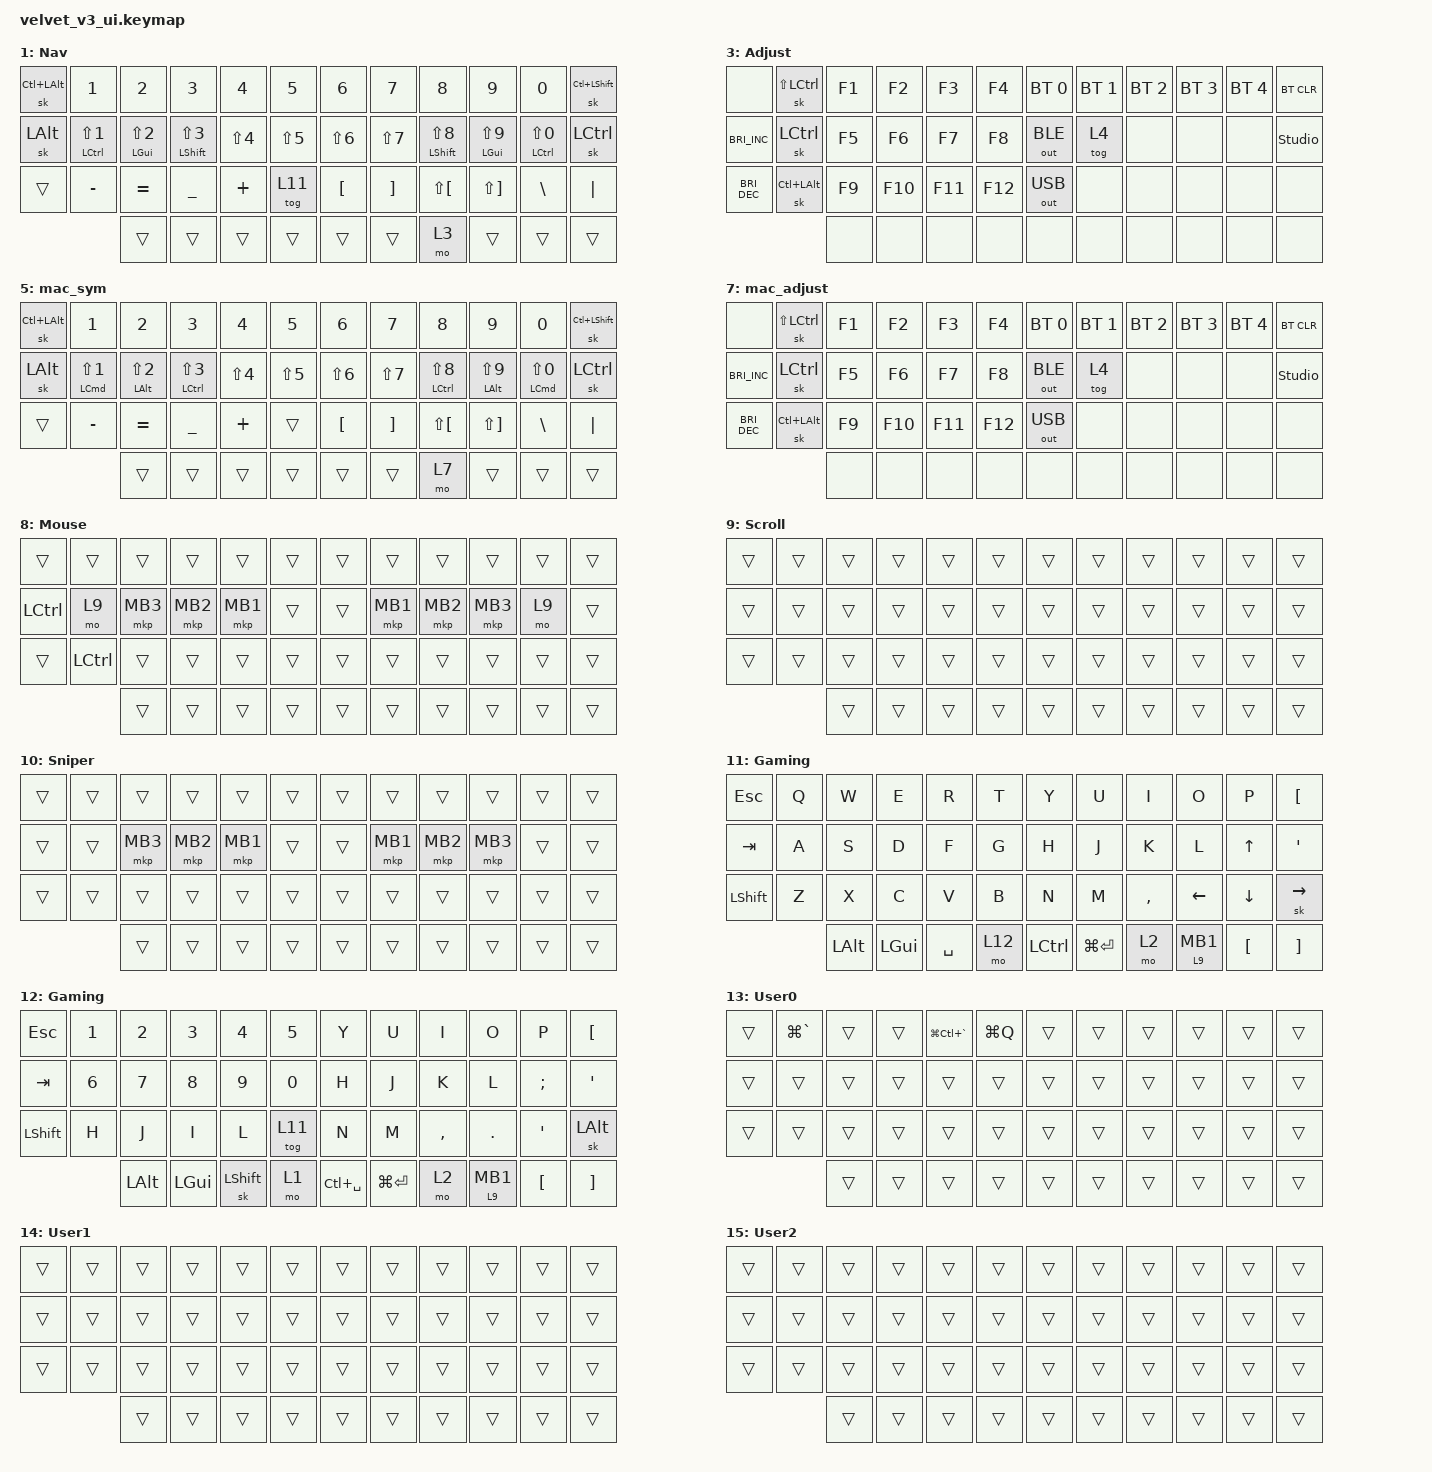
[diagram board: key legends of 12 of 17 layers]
#include "keys_ru.h"
#include <dt-bindings/zmk/input_transform.h>
#include <input/processors.dtsi>
#include <zephyr/dt-bindings/input/input-event-codes.h>
#include <behaviors.dtsi>
#include <dt-bindings/zmk/bt.h>
#include <dt-bindings/zmk/keys.h>
#include <dt-bindings/zmk/outputs.h>
#include <dt-bindings/zmk/pointing.h>

/ {
    behaviors {
        cap_sen: cap_sen {
            compatible = "zmk,behavior-hold-tap";
            label = "CAP_SEN";
            bindings = <&mo>, <&none>;

            #binding-cells = <2>;
            tapping-term-ms = <150>;
            hold-while-undecided;
        };

        hrm: hrm {
            compatible = "zmk,behavior-hold-tap";
            label = "HRM";
            bindings = <&kp>, <&kp>;

            #binding-cells = <2>;
            flavor = "balanced";
            tapping-term-ms = <200>;
            quick-tap-ms = <150>;
            require-prior-idle-ms = <50>;
        };

        th_cl: th_cl {
            compatible = "zmk,behavior-hold-tap";
            label = "TH_CL";
            bindings = <&mo>, <&kp>;

            #binding-cells = <2>;
            tapping-term-ms = <200>;
            flavor = "hold-preferred";
        };

        tball_mode: tball_mode {
            compatible = "zmk,behavior-hold-tap";
            label = "TBALL_MODE";
            bindings = <&mo>, <&tog>;

            #binding-cells = <2>;
            tapping-term-ms = <180>;
            flavor = "tap-preferred";
        };
    };

    combos {
        compatible = "zmk,combos";

        jk {
            bindings = <&jk LG(F12)>;
            key-positions = <19 20>;
            layers = <0 2 1 3>;
            require-prior-idle-ms = <50>;
        };

        ctrl-z {
            bindings = <&kp LC(Z)>;
            key-positions = <25 26>;
            require-prior-idle-ms = <50>;
            layers = <0 9 9>;
        };

        ctrl-x {
            bindings = <&kp LC(X)>;
            key-positions = <26 27>;
            require-prior-idle-ms = <50>;
            layers = <0 9 9>;
        };

        ctrl-c {
            bindings = <&kp LC(C)>;
            key-positions = <27 28>;
            require-prior-idle-ms = <50>;
            layers = <0 9 9>;
        };

        ctrl-v {
            bindings = <&kp LC(V)>;
            key-positions = <28 29>;
            require-prior-idle-ms = <50>;
            layers = <0 9 9>;
        };

        Escape {
            bindings = <&kp ESC>;
            key-positions = <2 3>;
            require-prior-idle-ms = <50>;
            layers = <0 9 9 9 4>;
        };

        m1 {
            bindings = <&mkp MB1>;
            key-positions = <15 16>;
            layers = <0 9 4>;
        };

        mk2 {
            bindings = <&mkp MB2>;
            key-positions = <16 17>;
            layers = <0 9 4>;
        };

        mk3 {
            bindings = <&mkp MB3>;
            key-positions = <16 17 15>;
            layers = <0 9 4>;
        };

        scroll {
            bindings = <&mo 9>;
            key-positions = <14 15>;
            layers = <0 9 4>;
        };

        mk3_double {
            bindings = <&mkp MB3>;
            key-positions = <44 45>;
        };

        jk_mac {
            bindings = <&kp LC(LEFT_BRACKET)>;
            key-positions = <19 20>;
            require-prior-idle-ms = <50>;
            layers = <9 4>;
        };

        macz {
            bindings = <&kp LG(Z)>;
            key-positions = <25 26>;
            require-prior-idle-ms = <50>;
            layers = <9 4>;
        };

        macx {
            bindings = <&kp LG(X)>;
            key-positions = <26 27>;
            require-prior-idle-ms = <50>;
            layers = <9 4>;
        };

        macc {
            bindings = <&kp LG(C)>;
            key-positions = <27 28>;
            require-prior-idle-ms = <50>;
            layers = <9 4>;
        };

        macv {
            bindings = <&kp LG(V)>;
            key-positions = <28 29>;
            require-prior-idle-ms = <50>;
            layers = <9 4>;
        };

        Sniper {
            bindings = <&mo 10>;
            key-positions = <3 4>;
        };
    };

    macros {
        jk: jk {
            compatible = "zmk,behavior-macro-one-param";
            #binding-cells = <1>;
            bindings =
                <&macro_param_1to1 &kp MACRO_PLACEHOLDER>,
                <&macro_wait_time 30>,
                <&kp LC(LEFT_BRACKET)>;

            label = "JK";
        };

        sen_mo: sen_mo {
            compatible = "zmk,behavior-macro-one-param";
            #binding-cells = <1>;
            bindings =
                <&macro_wait_time 80>,
                <&macro_press>,
                <&macro_param_1to1 &mo MACRO_PLACEHOLDER>,
                <&macro_pause_for_release>,
                <&macro_release>,
                <&macro_param_1to1 &mo MACRO_PLACEHOLDER>;

            label = "SEN_MO";
        };

        bt0_lin: bt0_lin {
            compatible = "zmk,behavior-macro";
            #binding-cells = <0>;
            bindings =
                <&macro_tap>,
                <&bt BT_SEL 0>,
                <&macro_tap>,
                <&tog 0>,
                <&macro_press>;

            label = "BT0_LIN";
        };

        bt1_mac: bt1_mac {
            compatible = "zmk,behavior-macro";
            #binding-cells = <0>;
            bindings =
                <&macro_tap>,
                <&tog 0>,
                <&macro_tap>,
                <&bt BT_SEL 1>,
                <&macro_tap>,
                <&tog 9>;

            label = "BT1_MAC";
        };
    };

    keymap {
        compatible = "zmk,keymap";

        base {
            bindings = <
&lt 13 GRAVE  &kp Q         &kp W            &kp E         &kp R           &kp T                                                                         &kp Y                        &kp U  &kp I      &kp O            &kp P            &kp LEFT_BRACKET
&kp TAB       &hrm LCTRL A  &hrm LEFT_GUI S  &kp D         &kp F           &hrm LS(LA(LC(LEFT_GUI))) G                                                   &hrm LS(LA(LC(LEFT_GUI))) H  &kp J  &kp K      &hrm LEFT_GUI L  &hrm LCTRL SEMI  &kp SINGLE_QUOTE
&caps_word    &kp Z         &kp X            &kp C         &kp V           &kp B                                                                         &kp N                        &kp M  &kp COMMA  &kp DOT          &kp SLASH        &sk LEFT_ALT
                            &kp LEFT_ALT     &kp CAPSLOCK  &sk LEFT_SHIFT  &th_cl 1 BACKSPACE           &hrm LC(LEFT_SHIFT) CAPSLOCK    &hrm LGUI ENTER  &th_cl 2 SPACE               &none  &mkp LCLK  &mkp RCLK
            >;

            display-name = "Base";
        };

        sym {
            bindings = <
&sk LC(LEFT_ALT)  &kp N1             &kp N2                      &kp N3                  &kp N4            &kp N5                              &kp N6            &kp N7             &kp N8                  &kp N9                 &kp N0             &sk LC(LEFT_SHIFT)
&sk LEFT_ALT      &hrm LCTRL LS(N1)  &hrm LEFT_GUI LS(NUMBER_2)  &hrm LEFT_SHIFT LS(N3)  &kp LS(NUMBER_4)  &kp LS(NUMBER_5)                    &kp LS(NUMBER_6)  &kp LS(NUMBER_7)   &hrm LEFT_SHIFT LS(N8)  &hrm LEFT_GUI LS(N9)   &hrm LCTRL LS(N0)  &sk LCTRL
&trans            &kp MINUS          &kp EQUAL                   &kp UNDER               &kp PLUS          &tog 11                             &kp LEFT_BRACKET  &kp RIGHT_BRACKET  &kp LS(LEFT_BRACKET)    &kp LS(RIGHT_BRACKET)  &kp BACKSLASH      &kp PIPE
                                     &trans                      &trans                  &trans            &trans            &trans    &trans  &mo 3             &trans             &trans                  &trans
            >;

            display-name = "Nav";
        };

        nav {
            bindings = <
&trans  &kp LG(PRINTSCREEN)  &kp PRINTSCREEN  &kp LC(LS(RIGHT_BRACKET))  &kp LS(LC(LA(LG(R))))  &none                          &kp C_PREVIOUS  &kp C_NEXT      &kp C_PP       &kp C_MUTE       &kp C_VOLUME_DOWN  &kp C_VOLUME_UP
&trans  &trans               &kp LC(N6)       &kp LC(PAGE_UP)            &kp LC(PAGE_DOWN)      &none                          &kp LEFT_ARROW  &kp DOWN_ARROW  &kp UP_ARROW   &kp RIGHT_ARROW  &kp DELETE         &kp INSERT
&trans  &trans               &none            &kp LC(LEFT_BRACKET)       &kp LC(RIGHT_BRACKET)  &none                          &kp HOME        &kp PAGE_DOWN   &kp PAGE_UP    &kp END          &kp LC(K_MUTE)     &kp ESC
                             &trans           &trans                     &trans                 &mo 3  &kp CAPSLOCK    &trans  &trans          &trans          &kp LC(PG_UP)  &kp LC(PG_DN)
            >;

            display-name = "Navigation";
        };

        adj {
            bindings = <
&none                 &sk LS(LCTRL)     &kp F1  &kp F2   &kp F3   &kp F4                   &bt BT_SEL 0  &bt BT_SEL 1  &bt BT_SEL 2  &bt BT_SEL 3  &bt BT_SEL 4  &bt BT_CLR
&kp C_BRIGHTNESS_INC  &sk LCTRL         &kp F5  &kp F6   &kp F7   &kp F8                   &out OUT_BLE  &tog 4        &none         &none         &none         &studio_unlock
&kp C_BRIGHTNESS_DEC  &sk LC(LEFT_ALT)  &kp F9  &kp F10  &kp F11  &kp F12                  &out OUT_USB  &none         &none         &none         &none         &none
                                        &none   &none    &none    &none    &none    &none  &none         &none         &none         &none
            >;

            display-name = "Adjust";
        };

        mac_base {
            display-name = "MAC Base";
            bindings = <
&lt 13 GRAVE  &kp Q        &kp W            &kp E          &kp R           &kp T                                                          &kp Y                        &kp U  &kp I         &kp O            &kp P           &kp LEFT_BRACKET
&kp TAB       &hrm LCMD A  &hrm LEFT_ALT S  &hrm LCTRL D   &kp F           &hrm LS(LA(LC(LEFT_GUI))) G                                    &hrm LS(LA(LC(LEFT_GUI))) H  &kp J  &hrm LCTRL K  &hrm LEFT_ALT L  &hrm LCMD SEMI  &kp SINGLE_QUOTE
&caps_word    &kp Z        &kp X            &kp C          &kp V           &kp B                                                          &kp N                        &kp M  &kp COMMA     &kp DOT          &kp SLASH       &sk LEFT_ALT
                           &kp LEFT_ALT     &sk LS(LCTRL)  &sk LEFT_SHIFT  &th_cl 5 BACKSPACE           &kp CAPSLOCK    &hrm LCTRL ENTER  &th_cl 6 SPACE               &none  &mkp LCLK     &mkp RCLK
            >;
        };

        mac_sym {
            display-name = "mac_sym";
            bindings = <
&sk LC(LEFT_ALT)  &kp N1            &kp N2                      &kp N3             &kp N4            &kp N5                              &kp N6            &kp N7             &kp N8                &kp N9                 &kp N0                    &sk LC(LEFT_SHIFT)
&sk LEFT_ALT      &hrm LCMD LS(N1)  &hrm LEFT_ALT LS(NUMBER_2)  &hrm LCTRL LS(N3)  &kp LS(NUMBER_4)  &kp LS(NUMBER_5)                    &kp LS(NUMBER_6)  &kp LS(NUMBER_7)   &hrm LCTRL LS(N8)     &hrm LEFT_ALT LS(N9)   &hrm LEFT_COMMAND LS(N0)  &sk LCTRL
&trans            &kp MINUS         &kp EQUAL                   &kp UNDER          &kp PLUS          &trans                              &kp LEFT_BRACKET  &kp RIGHT_BRACKET  &kp LS(LEFT_BRACKET)  &kp LS(RIGHT_BRACKET)  &kp BACKSLASH             &kp PIPE
                                    &trans                      &trans             &trans            &trans            &trans    &trans  &mo 7             &trans             &trans                &trans
            >;
        };

        mac_nav {
            display-name = "mac_nav";
            bindings = <
&trans  &kp LG(PRINTSCREEN)  &kp LG(LS(F4))  &kp LC(LS(RIGHT_BRACKET))  &kp LS(LC(LA(LG(R))))  &none                          &kp C_PREV      &kp C_NEXT      &kp C_PP       &kp K_MUTE       &kp C_VOLUME_DOWN  &kp C_VOLUME_UP
&trans  &trans               &kp LC(N6)      &kp LC(LS(TAB))            &kp LC(TAB)            &none                          &kp LEFT_ARROW  &kp DOWN_ARROW  &kp UP_ARROW   &kp RIGHT_ARROW  &kp DELETE         &kp INSERT
&trans  &trans               &none           &kp LG(LEFT_BRACKET)       &kp LG(RIGHT_BRACKET)  &none                          &kp HOME        &kp PAGE_DOWN   &kp PAGE_UP    &kp END          &kp LA(LC(F12))    &kp ESC
                             &trans          &trans                     &trans                 &mo 7  &kp CAPSLOCK    &trans  &trans          &trans          &kp LC(PG_UP)  &kp LC(PG_DN)
            >;
        };

        mac_adjust {
            display-name = "mac_adjust";
            bindings = <
&none                 &sk LS(LCTRL)     &kp F1  &kp F2   &kp F3   &kp F4                   &bt BT_SEL 0  &bt BT_SEL 1  &bt BT_SEL 2  &bt BT_SEL 3  &bt BT_SEL 4  &bt BT_CLR
&kp C_BRIGHTNESS_INC  &sk LCTRL         &kp F5  &kp F6   &kp F7   &kp F8                   &out OUT_BLE  &tog 4        &none         &none         &none         &studio_unlock
&kp C_BRIGHTNESS_DEC  &sk LC(LEFT_ALT)  &kp F9  &kp F10  &kp F11  &kp F12                  &out OUT_USB  &none         &none         &none         &none         &none
                                        &none   &none    &none    &none    &none    &none  &none         &none         &none         &none
            >;
        };

        mouse {
            bindings = <
&trans     &trans     &trans    &trans    &trans    &trans                    &trans  &trans    &trans    &trans    &trans  &trans
&kp LCTRL  &mo 9      &mkp MB3  &mkp MB2  &mkp MB1  &trans                    &trans  &mkp MB1  &mkp MB2  &mkp MB3  &mo 9   &trans
&trans     &kp LCTRL  &trans    &trans    &trans    &trans                    &trans  &trans    &trans    &trans    &trans  &trans
                      &trans    &trans    &trans    &trans  &trans    &trans  &trans  &trans    &trans    &trans
            >;

            display-name = "Mouse";
        };

        scroll {
            bindings = <
&trans  &trans  &trans  &trans  &trans  &trans                    &trans  &trans  &trans  &trans  &trans  &trans
&trans  &trans  &trans  &trans  &trans  &trans                    &trans  &trans  &trans  &trans  &trans  &trans
&trans  &trans  &trans  &trans  &trans  &trans                    &trans  &trans  &trans  &trans  &trans  &trans
                &trans  &trans  &trans  &trans  &trans    &trans  &trans  &trans  &trans  &trans
            >;

            display-name = "Scroll";
        };

        sniper {
            bindings = <
&trans  &trans  &trans    &trans    &trans    &trans                    &trans  &trans    &trans    &trans    &trans  &trans
&trans  &trans  &mkp MB3  &mkp MB2  &mkp MB1  &trans                    &trans  &mkp MB1  &mkp MB2  &mkp MB3  &trans  &trans
&trans  &trans  &trans    &trans    &trans    &trans                    &trans  &trans    &trans    &trans    &trans  &trans
                &trans    &trans    &trans    &trans  &trans    &trans  &trans  &trans    &trans    &trans
            >;

            display-name = "Sniper";
        };

        game {
            display-name = "Gaming";
            bindings = <
&kp ESC         &kp Q  &kp W     &kp E     &kp R      &kp T                             &kp Y  &kp U           &kp I      &kp O           &kp P           &kp LEFT_BRACKET
&kp TAB         &kp A  &kp S     &kp D     &kp F      &kp G                             &kp H  &kp J           &kp K      &kp L           &kp UP_ARROW    &kp SINGLE_QUOTE
&kp LEFT_SHIFT  &kp Z  &kp X     &kp C     &kp V      &kp B                             &kp N  &kp M           &kp COMMA  &kp LEFT_ARROW  &kp DOWN_ARROW  &sk RIGHT_ARROW
                       &kp LALT  &kp LGUI  &kp SPACE  &mo 12  &kp LCTRL    &kp LG(RET)  &mo 2  &cap_sen 9 MB1  &kp LBKT   &kp RBKT
            >;
        };

        game_2 {
            display-name = "Gaming";
            bindings = <
&kp ESC         &kp NUMBER_1  &kp N2    &kp N3    &kp N4          &kp N5                                 &kp Y  &kp U           &kp I      &kp O     &kp P     &kp LEFT_BRACKET
&kp TAB         &kp N6        &kp N7    &kp N8    &kp N9          &kp N0                                 &kp H  &kp J           &kp K      &kp L     &kp SEMI  &kp SINGLE_QUOTE
&kp LEFT_SHIFT  &kp H         &kp J     &kp I     &kp L           &tog 11                                &kp N  &kp M           &kp COMMA  &kp DOT   &kp SQT   &sk LEFT_ALT
                              &kp LALT  &kp LGUI  &sk LEFT_SHIFT  &mo 1    &kp LC(SPACE)    &kp LG(RET)  &mo 2  &cap_sen 9 MB1  &kp LBKT   &kp RBKT
            >;
        };

        User0 {
            bindings = <
&trans  &kp LG(GRAVE)  &trans  &trans  &kp LG(LC(GRAVE))  &kp LG(Q)                    &trans  &trans  &trans  &trans  &trans  &trans
&trans  &trans         &trans  &trans  &trans             &trans                       &trans  &trans  &trans  &trans  &trans  &trans
&trans  &trans         &trans  &trans  &trans             &trans                       &trans  &trans  &trans  &trans  &trans  &trans
                       &trans  &trans  &trans             &trans     &trans    &trans  &trans  &trans  &trans  &trans
            >;

            display-name = "User0";
        };

        User1 {
            bindings = <
&trans  &trans  &trans  &trans  &trans  &trans                    &trans  &trans  &trans  &trans  &trans  &trans
&trans  &trans  &trans  &trans  &trans  &trans                    &trans  &trans  &trans  &trans  &trans  &trans
&trans  &trans  &trans  &trans  &trans  &trans                    &trans  &trans  &trans  &trans  &trans  &trans
                &trans  &trans  &trans  &trans  &trans    &trans  &trans  &trans  &trans  &trans
            >;

            display-name = "User1";
        };

        User2 {
            bindings = <
&trans  &trans  &trans  &trans  &trans  &trans                    &trans  &trans  &trans  &trans  &trans  &trans
&trans  &trans  &trans  &trans  &trans  &trans                    &trans  &trans  &trans  &trans  &trans  &trans
&trans  &trans  &trans  &trans  &trans  &trans                    &trans  &trans  &trans  &trans  &trans  &trans
                &trans  &trans  &trans  &trans  &trans    &trans  &trans  &trans  &trans  &trans
            >;

            display-name = "User2";
        };

        User3 {
            bindings = <
&trans  &trans  &trans  &trans  &trans  &trans                    &trans  &trans  &trans  &trans  &trans  &trans
&trans  &trans  &trans  &trans  &trans  &trans                    &trans  &trans  &trans  &trans  &trans  &trans
&trans  &trans  &trans  &trans  &trans  &trans                    &trans  &trans  &trans  &trans  &trans  &trans
                &trans  &trans  &trans  &trans  &trans    &trans  &trans  &trans  &trans  &trans
            >;

            display-name = "User3";
        };
    };
};

&trackball { cpi = <1600>; };

&trackball_listener {
    input-processors = <&zip_xy_scaler 9 20>;

    scroller {
        layers = <9>;
        input-processors =
            <&zip_xy_transform INPUT_TRANSFORM_Y_INVERT>,
            <&zip_xy_scaler 1 32>,
            <&zip_xy_to_scroll_mapper>;
    };

    sniper {
        layers = <10>;
        input-processors = <&zip_xy_scaler 1 4>;
    };
};
